# ATmega2561 device description
Architecture: AVR8; Family: megaAVR
Registers are 8-bit, access not given, no defined reset value unless marked. A register's access mark holds for its fields unless they carry their own. Offsets are from the block's base; [hi:lo] are bit positions; {n}, {i} and the like mark numbered series.

## ADC — Analog-to-Digital Converter
Instances: ADC 0x00
0x78 ADC 16-bit — ADC Data Register Bytes
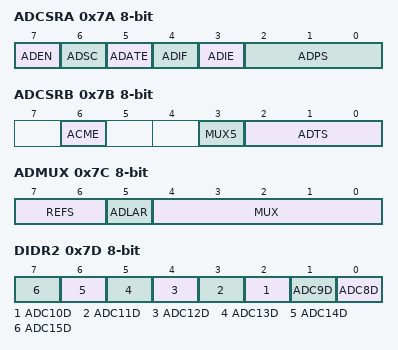
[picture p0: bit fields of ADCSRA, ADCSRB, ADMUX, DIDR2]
0x7A ADCSRA — The ADC Control and Status register A
  [7] ADEN — ADC Enable
  [6] ADSC — ADC Start Conversion
  [5] ADATE — ADC Auto Trigger Enable
  [4] ADIF — ADC Interrupt Flag
  [3] ADIE — ADC Interrupt Enable
  [2:0] ADPS — ADC Prescaler Select Bits
    0=2; 1=2; 2=4; 3=8; 4=16; 5=32; 6=64; 7=128
0x7B ADCSRB — The ADC Control and Status register B
  [6] ACME
  [3] MUX5 — Analog Channel and Gain Selection Bits
  [2:0] ADTS — ADC Auto Trigger Source bits
    0=FREE_RUNNING_MODE; 1=ANALOG_COMPARATOR; 2=EXTERNAL_INTERRUPT_REQUEST_0; 3=TIMER_COUNTER0_COMPARE_MATCH_A; 4=TIMER_COUNTER0_OVERFLOW; 5=TIMER_COUNTER1_COMPARE_MATCH_B; 6=TIMER_COUNTER1_OVERFLOW; 7=TIMER_COUNTER1_CAPTURE_EVENT
0x7C ADMUX — The ADC multiplexer Selection Register
  [7:6] REFS — Reference Selection Bits
    0=AREF_INTERNAL_VREF_TURNED_OFF; 1=AVCC_WITH_EXTERNAL_CAPACITOR_AT_AREF_PIN; 2=INTERNAL_1_1V_VOLTAGE_REFERENCE_WITH_EXTERNAL_CAPACITOR_AT_AREF_PIN; 3=INTERNAL_2_56V_VOLTAGE_REFERENCE_WITH_EXTERNAL_CAPACITOR_AT_AREF_PIN
  [5] ADLAR — Left Adjust Result
  [4:0] MUX — Analog Channel and Gain Selection Bits
    {v}=ADC{v} (ADC Single Ended Input pin {v}) (v=0..7); 8=ADC0_ADC0_10X (ADC Differential Inputs Positive pin 0 Negative pin 0 10x Gain); 9=ADC1_ADC0_10X (ADC Differential Inputs Positive pin 1 Negative pin 0 10x Gain); 10=ADC0_ADC0_200x (ADC Differential Inputs Positive pin 0 Negative pin 0 200x Gain); 11=ADC1_ADC0_200X (ADC Differential Inputs Positive pin 1 Negative pin 0 200x Gain); 12=ADC2_ADC2_10X (ADC Differential Inputs Positive pin 2 Negative pin 2 10x Gain); 13=ADC3_ADC2_10X (ADC Differential Inputs Positive pin 3 Negative pin 2 10x Gain); 14=ADC2_ADC2_200X (ADC Differential Inputs Positive pin 2 Negative pin 2 200x Gain); 15=ADC3_ADC2_200X (ADC Differential Inputs Positive pin 3 Negative pin 2 200x Gain); {v}=ADC{v-16}_ADC1_1X (ADC Differential Inputs Positive pin {v-16} Negative pin 1 1x Gain) (v=16..23); {v}=ADC{v-24}_ADC2_1X (ADC Differential Inputs Positive pin {v-24} Negative pin 2 1x Gain) (v=24..29); 30=ADC_VBG (Internal Reference (VBG)); 31=ADC_GND (0V (GND)); {v}=ADC{v-24} (ADC Single Ended Input pin {v-24}) (v=32..39); 40=ADC8_ADC8_10X (ADC Differential Inputs Positive pin 8 Negative pin 8 10x Gain); 41=ADC9_ADC8_10X (ADC Differential Inputs Positive pin 9 Negative pin 8 10x Gain); 42=ADC8_ADC8_200x (ADC Differential Inputs Positive pin 8 Negative pin 8 200x Gain); 43=ADC9_ADC8_200X (ADC Differential Inputs Positive pin 9 Negative pin 8 200x Gain); 44=ADC10_ADC10_10X (ADC Differential Inputs Positive pin 10 Negative pin 10 10x Gain); 45=ADC11_ADC10_10X (ADC Differential Inputs Positive pin 11 Negative pin 10 10x Gain); 46=ADC10_ADC10_200X (ADC Differential Inputs Positive pin 10 Negative pin 10 200x Gain); 47=ADC11_ADC10_200X (ADC Differential Inputs Positive pin 11 Negative pin 10 200x Gain); {v}=ADC{v-40}_ADC9_1X (ADC Differential Inputs Positive pin {v-40} Negative pin 9 1x Gain) (v=48..55); {v}=ADC{v-48}_ADC10_1X (ADC Differential Inputs Positive pin {v-48} Negative pin 10 1x Gain) (v=56..61)
0x7D DIDR2 — Digital Input Disable Register
  [n-8] ADC{n}D (n=8..15)
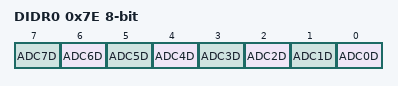
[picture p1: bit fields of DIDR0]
0x7E DIDR0 — Digital Input Disable Register
  [n] ADC{n}D (n=0..7)

## BOOT_LOAD — Bootloader
Instances: BOOT_LOAD 0x00
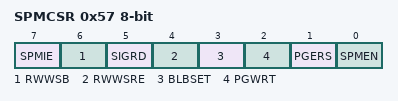
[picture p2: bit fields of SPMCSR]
0x57 SPMCSR — Store Program Memory Control Register
  [7] SPMIE — SPM Interrupt Enable
  [6] RWWSB — Read While Write Section Busy
  [5] SIGRD — Signature Row Read
  [4] RWWSRE — Read While Write section read enable
  [3] BLBSET — Boot Lock Bit Set
  [2] PGWRT — Page Write
  [1] PGERS — Page Erase
  [0] SPMEN — Store Program Memory Enable
